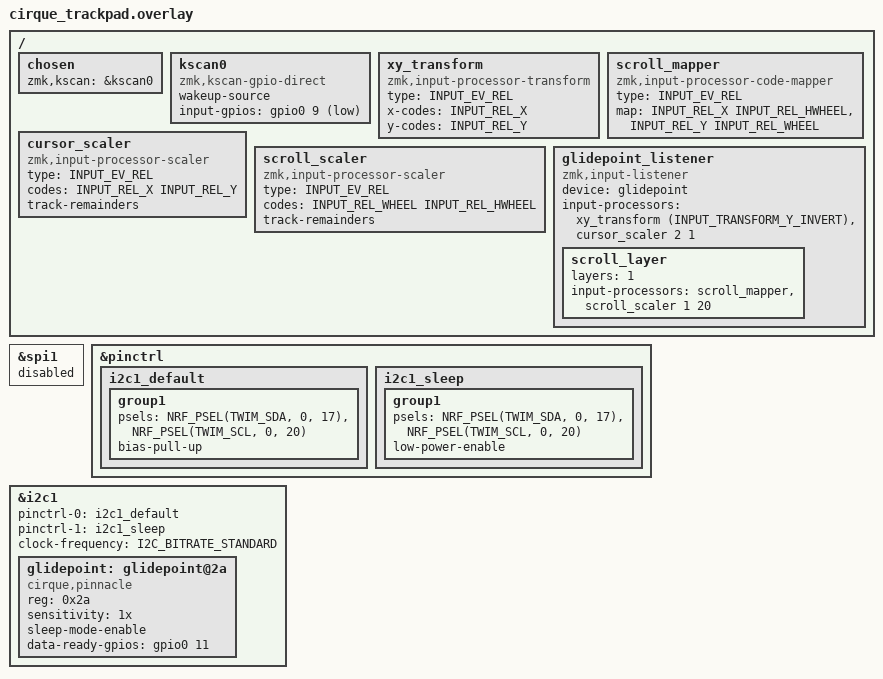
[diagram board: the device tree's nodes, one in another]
#include <dt-bindings/zmk/input_transform.h>
#include <zephyr/dt-bindings/input/input-event-codes.h>

/ {
    chosen {
        zmk,kscan = &kscan0;
    };

    kscan0: kscan0 {
        compatible = "zmk,kscan-gpio-direct";
        wakeup-source;
        input-gpios = <&gpio0 9 (GPIO_ACTIVE_LOW | GPIO_PULL_UP)>;
    };

    xy_transform: xy_transform {
        compatible = "zmk,input-processor-transform";
        #input-processor-cells = <1>;
        type = <INPUT_EV_REL>;
        x-codes = <INPUT_REL_X>;
        y-codes = <INPUT_REL_Y>;
    };

    scroll_mapper: scroll_mapper {
        compatible = "zmk,input-processor-code-mapper";
        #input-processor-cells = <0>;
        type = <INPUT_EV_REL>;
        map = <INPUT_REL_X INPUT_REL_HWHEEL>
            , <INPUT_REL_Y INPUT_REL_WHEEL>;
    };

    cursor_scaler: cursor_scaler {
        compatible = "zmk,input-processor-scaler";
        #input-processor-cells = <2>;
        type = <INPUT_EV_REL>;
        codes = <INPUT_REL_X INPUT_REL_Y>;
        track-remainders;
    };

    scroll_scaler: scroll_scaler {
        compatible = "zmk,input-processor-scaler";
        #input-processor-cells = <2>;
        type = <INPUT_EV_REL>;
        codes = <INPUT_REL_WHEEL INPUT_REL_HWHEEL>;
        /* Accumulate fractional deltas instead of truncating to zero — without this, slow finger movements produce no scroll at all */
        track-remainders;
    };

    glidepoint_listener: glidepoint_listener {
        compatible = "zmk,input-listener";
        device = <&glidepoint>;
        input-processors = <&xy_transform (INPUT_TRANSFORM_Y_INVERT) &cursor_scaler 2 1>;

        scroll_layer {
            layers = <1>;
            input-processors = <&scroll_mapper &scroll_scaler 1 20>;
        };
    };
};

/* SPIM1 and TWIM1 share hardware on nRF52840 — disable SPI so I2C works */
&spi1 {
    status = "disabled";
};

&pinctrl {
    i2c1_default: i2c1_default {
        group1 {
            psels = <NRF_PSEL(TWIM_SDA, 0, 17)>,
                    <NRF_PSEL(TWIM_SCL, 0, 20)>;
            bias-pull-up;
        };
    };

    i2c1_sleep: i2c1_sleep {
        group1 {
            psels = <NRF_PSEL(TWIM_SDA, 0, 17)>,
                    <NRF_PSEL(TWIM_SCL, 0, 20)>;
            low-power-enable;
        };
    };
};

&i2c1 {
    status = "okay";
    pinctrl-0 = <&i2c1_default>;
    pinctrl-1 = <&i2c1_sleep>;
    pinctrl-names = "default", "sleep";
    clock-frequency = <I2C_BITRATE_STANDARD>;

    glidepoint: glidepoint@2a {
        compatible = "cirque,pinnacle";
        reg = <0x2a>;
        status = "okay";
        sensitivity = "1x";
        sleep-mode-enable;
        data-ready-gpios = <&gpio0 11 GPIO_ACTIVE_HIGH>;
    };
};
